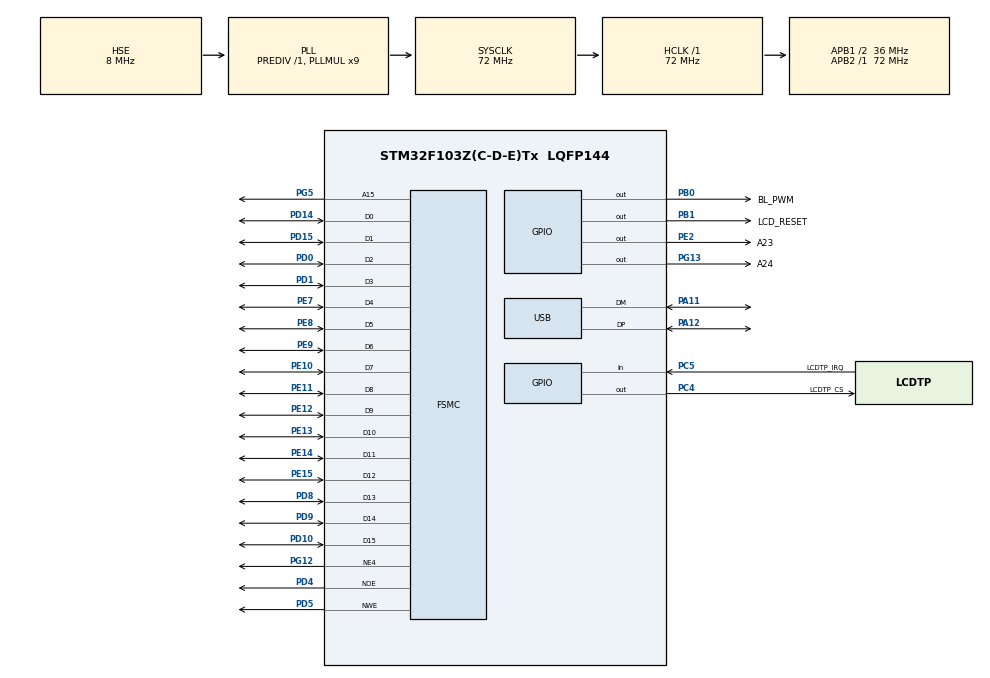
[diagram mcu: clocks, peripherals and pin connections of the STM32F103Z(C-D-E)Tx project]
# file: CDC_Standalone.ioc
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Mcu.Family=STM32F1
Mcu.Name=STM32F103Z(C-D-E)Tx
Mcu.Package=LQFP144
NVIC.PriorityGroup=NVIC_PRIORITYGROUP_4
NVIC.USB_LP_CAN1_RX0_IRQn=true\:0\:0\:false\:false\:true
OSC_IN.Mode=HSE-External-Oscillator
OSC_IN.Signal=RCC_OSC_IN
OSC_OUT.Mode=HSE-External-Oscillator
OSC_OUT.Signal=RCC_OSC_OUT
PA11.Mode=Device
PA11.Signal=USB_DM
PA12.Mode=Device
PA12.Signal=USB_DP
PB0.GPIO_Label=BL_PWM
PB0.Signal=GPIO_Output
PB1.GPIO_Label=LCD_RESET
PB1.Signal=GPIO_Output
PC4.GPIO_Label=LCDTP_CS
PC4.Signal=GPIO_Output
PC5.GPIO_Label=LCDTP_IRQ
PC5.Signal=GPIO_Input
PD0.Signal=FSMC_D2_DA2
PD1.Signal=FSMC_D3_DA3
PD10.Signal=FSMC_D15_DA15
PD14.Signal=FSMC_D0_DA0
PD15.Signal=FSMC_D1_DA1
PD4.Signal=FSMC_NOE
PD5.Signal=FSMC_NWE
PD8.Signal=FSMC_D13_DA13
PD9.Signal=FSMC_D14_DA14
PE10.Signal=FSMC_D7_DA7
PE11.Signal=FSMC_D8_DA8
PE12.Signal=FSMC_D9_DA9
PE13.Signal=FSMC_D10_DA10
PE14.Signal=FSMC_D11_DA11
PE15.Signal=FSMC_D12_DA12
PE2.GPIO_Label=A23
PE2.PinState=GPIO_PIN_SET
PE2.Signal=GPIO_Output
PE7.Signal=FSMC_D4_DA4
PE8.Signal=FSMC_D5_DA5
PE9.Signal=FSMC_D6_DA6
PG12.Mode=NorPsramChipSelect4_1
PG12.Signal=FSMC_NE4
PG13.GPIO_Label=A24
PG13.PinState=GPIO_PIN_SET
PG13.Signal=GPIO_Output
PG5.Signal=FSMC_A15
ProjectManager.HeapSize=0x400
ProjectManager.StackSize=0x200
ProjectManager.TargetToolchain=MDK-ARM V5
RCC.AHBFreq_Value=72000000
RCC.APB1CLKDivider=RCC_HCLK_DIV2
RCC.APB1Freq_Value=36000000
RCC.APB1TimFreq_Value=72000000
RCC.APB2Freq_Value=72000000
RCC.APB2TimFreq_Value=72000000
RCC.HCLKFreq_Value=72000000
RCC.HSIState=RCC_HSI_ON
RCC.PLLMUL=RCC_PLL_MUL9
RCC.SYSCLKFreq_VALUE=72000000
RCC.SYSCLKSource=RCC_SYSCLKSOURCE_PLLCLK
RCC.USBFreq_Value=48000000
RCC.USBPrescaler=RCC_USBCLKSOURCE_PLL_DIV1_5
SH.FSMC_A15.0=FSMC_A15,A15_1
SH.FSMC_D0_DA0.0=FSMC_D0,16b-d1
SH.FSMC_D10_DA10.0=FSMC_D10,16b-d1
SH.FSMC_D11_DA11.0=FSMC_D11,16b-d1
SH.FSMC_D12_DA12.0=FSMC_D12,16b-d1
SH.FSMC_D13_DA13.0=FSMC_D13,16b-d1
SH.FSMC_D14_DA14.0=FSMC_D14,16b-d1
SH.FSMC_D15_DA15.0=FSMC_D15,16b-d1
SH.FSMC_D1_DA1.0=FSMC_D1,16b-d1
SH.FSMC_D2_DA2.0=FSMC_D2,16b-d1
SH.FSMC_D3_DA3.0=FSMC_D3,16b-d1
SH.FSMC_D4_DA4.0=FSMC_D4,16b-d1
SH.FSMC_D5_DA5.0=FSMC_D5,16b-d1
SH.FSMC_D6_DA6.0=FSMC_D6,16b-d1
SH.FSMC_D7_DA7.0=FSMC_D7,16b-d1
SH.FSMC_D8_DA8.0=FSMC_D8,16b-d1
SH.FSMC_D9_DA9.0=FSMC_D9,16b-d1
SH.FSMC_NOE.0=FSMC_NOE,Lcd1
SH.FSMC_NWE.0=FSMC_NWE,Lcd1
USB_DEVICE.CLASS_NAME_FS=CDC
USB_DEVICE.USBD_CDC_INTERVAL=5
USB_DEVICE.USBD_HandleTypeDef=hUsbDeviceFS
USB_DEVICE.USBD_MAX_STR_DESC_SIZ=48
USB_DEVICE.VirtualMode=Cdc
USB_DEVICE.VirtualModeFS=Cdc_FS
VP_SYS_VS_ND.Mode=No_Debug
VP_USB_DEVICE_VS_USB_DEVICE_CDC_FS.Mode=CDC_FS
board=CDC_Standalone

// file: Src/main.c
/**
  ******************************************************************************
  * File Name          : main.c
  * Description        : Main program body
  ******************************************************************************
  *
  * Copyright (c) 2016 STMicroelectronics International N.V.
  * All rights reserved.
  *
  * Redistribution and use in source and binary forms, with or without
  * modification, are permitted, provided that the following conditions are met:
  *
  * 1. Redistribution of source code must retain the above copyright notice,
  *    this list of conditions and the following disclaimer.
  * 2. Redistributions in binary form must reproduce the above copyright notice,
  *    this list of conditions and the following disclaimer in the documentation
  *    and/or other materials provided with the distribution.
  * 3. Neither the name of STMicroelectronics nor the names of other
  *    contributors to this software may be used to endorse or promote products
  *    derived from this software without specific written permission.
  * 4. This software, including modifications and/or derivative works of this
  *    software, must execute solely and exclusively on microcontroller or
  *    microprocessor devices manufactured by or for STMicroelectronics.
  * 5. Redistribution and use of this software other than as permitted under
  *    this license is void and will automatically terminate your rights under
  *    this license.
  *
  * THIS SOFTWARE IS PROVIDED BY STMICROELECTRONICS AND CONTRIBUTORS "AS IS"
  * AND ANY EXPRESS, IMPLIED OR STATUTORY WARRANTIES, INCLUDING, BUT NOT
  * LIMITED TO, THE IMPLIED WARRANTIES OF MERCHANTABILITY, FITNESS FOR A
  * PARTICULAR PURPOSE AND NON-INFRINGEMENT OF THIRD PARTY INTELLECTUAL PROPERTY
  * RIGHTS ARE DISCLAIMED TO THE FULLEST EXTENT PERMITTED BY LAW. IN NO EVENT
  * SHALL STMICROELECTRONICS OR CONTRIBUTORS BE LIABLE FOR ANY DIRECT, INDIRECT,
  * INCIDENTAL, SPECIAL, EXEMPLARY, OR CONSEQUENTIAL DAMAGES (INCLUDING, BUT NOT
  * LIMITED TO, PROCUREMENT OF SUBSTITUTE GOODS OR SERVICES; LOSS OF USE, DATA,
  * OR PROFITS; OR BUSINESS INTERRUPTION) HOWEVER CAUSED AND ON ANY THEORY OF
  * LIABILITY, WHETHER IN CONTRACT, STRICT LIABILITY, OR TORT (INCLUDING
  * NEGLIGENCE OR OTHERWISE) ARISING IN ANY WAY OUT OF THE USE OF THIS SOFTWARE,
  * EVEN IF ADVISED OF THE POSSIBILITY OF SUCH DAMAGE.
  *
  ******************************************************************************
  */
#include "main.h"
#include "stm32f1xx_hal.h"
#include "usb_device.h"
#include "gpio.h"
#include "fsmc.h"

/* USER CODE BEGIN Includes */
#include "stm3210x_lcd.h"
#include "lcd_log.h"
#include "usbd_cdc.h"
#include "usbd_cdc_if.h"
/* USER CODE END Includes */

/* USER CODE BEGIN PV */
/* Private variables ---------------------------------------------------------*/
extern struct netif gnetif;
/* USER CODE END PV */

void SystemClock_Config(void);
void Error_Handler(void);

/* USER CODE BEGIN PFP */
/* Private function prototypes -----------------------------------------------*/

/* USER CODE END PFP */

int main(void)
{

  /* USER CODE BEGIN 1 */
  uint8_t UserTxBuffer[] = "WaveShare Open103Z Board STM32 Virtual COM Port Driver \r\n";
  /* USER CODE END 1 */

  /* MCU Configuration----------------------------------------------------------*/

  /* Reset of all peripherals, Initializes the Flash interface and the Systick. */
  HAL_Init();

  /* Configure the system clock */
  SystemClock_Config();

  /* Initialize all configured peripherals */
  MX_GPIO_Init();
  MX_FSMC_Init();
  MX_USB_DEVICE_Init();

  /* USER CODE BEGIN 2 */
  BSP_LCD_Init();

  /* Initialize LCD Log module */
  LCD_LOG_Init();

  /* Show Header and Footer texts */
  LCD_LOG_SetHeader((uint8_t *)"Virtual COM Port");
  LCD_LOG_SetFooter((uint8_t *)"WaveShare Open103Z");

  /* USER CODE END 2 */

  /* Infinite loop */
  while (1)
  {

  /* USER CODE BEGIN 3 */

//    USBD_CDC_SetTxBuffer(&hUsbDeviceFS, (uint8_t*)&UserTxBuffer, sizeof(UserTxBuffer));
//    USBD_CDC_TransmitPacket(&hUsbDeviceFS);
    CDC_Transmit_FS((uint8_t*)&UserTxBuffer, sizeof(UserTxBuffer));
    HAL_Delay(1000);
  }
  /* USER CODE END 3 */

}

/** System Clock Configuration
*/
void SystemClock_Config(void)
{

  RCC_OscInitTypeDef RCC_OscInitStruct;
  RCC_ClkInitTypeDef RCC_ClkInitStruct;
  RCC_PeriphCLKInitTypeDef PeriphClkInit;

    /**Initializes the CPU, AHB and APB busses clocks
    */
  RCC_OscInitStruct.OscillatorType = RCC_OSCILLATORTYPE_HSE;
  RCC_OscInitStruct.HSEState = RCC_HSE_ON;
  RCC_OscInitStruct.HSEPredivValue = RCC_HSE_PREDIV_DIV1;
  RCC_OscInitStruct.HSIState = RCC_HSI_ON;
  RCC_OscInitStruct.PLL.PLLState = RCC_PLL_ON;
  RCC_OscInitStruct.PLL.PLLSource = RCC_PLLSOURCE_HSE;
  RCC_OscInitStruct.PLL.PLLMUL = RCC_PLL_MUL9;
  if (HAL_RCC_OscConfig(&RCC_OscInitStruct) != HAL_OK)
  {
    Error_Handler();
  }

    /**Initializes the CPU, AHB and APB busses clocks
    */
  RCC_ClkInitStruct.ClockType = RCC_CLOCKTYPE_HCLK|RCC_CLOCKTYPE_SYSCLK
                              |RCC_CLOCKTYPE_PCLK1|RCC_CLOCKTYPE_PCLK2;
  RCC_ClkInitStruct.SYSCLKSource = RCC_SYSCLKSOURCE_PLLCLK;
  RCC_ClkInitStruct.AHBCLKDivider = RCC_SYSCLK_DIV1;
  RCC_ClkInitStruct.APB1CLKDivider = RCC_HCLK_DIV2;
  RCC_ClkInitStruct.APB2CLKDivider = RCC_HCLK_DIV1;

  if (HAL_RCC_ClockConfig(&RCC_ClkInitStruct, FLASH_LATENCY_2) != HAL_OK)
  {
    Error_Handler();
  }

  PeriphClkInit.PeriphClockSelection = RCC_PERIPHCLK_USB;
  PeriphClkInit.UsbClockSelection = RCC_USBCLKSOURCE_PLL_DIV1_5;
  if (HAL_RCCEx_PeriphCLKConfig(&PeriphClkInit) != HAL_OK)
  {
    Error_Handler();
  }

    /**Configure the Systick interrupt time
    */
  HAL_SYSTICK_Config(HAL_RCC_GetHCLKFreq()/1000);

    /**Configure the Systick
    */
  HAL_SYSTICK_CLKSourceConfig(SYSTICK_CLKSOURCE_HCLK);

  /* SysTick_IRQn interrupt configuration */
  HAL_NVIC_SetPriority(SysTick_IRQn, 0, 0);
}

void Error_Handler(void)
{
  while(1)
  {
  }
}

/************************ (C) COPYRIGHT STMicroelectronics *****END OF FILE****/
